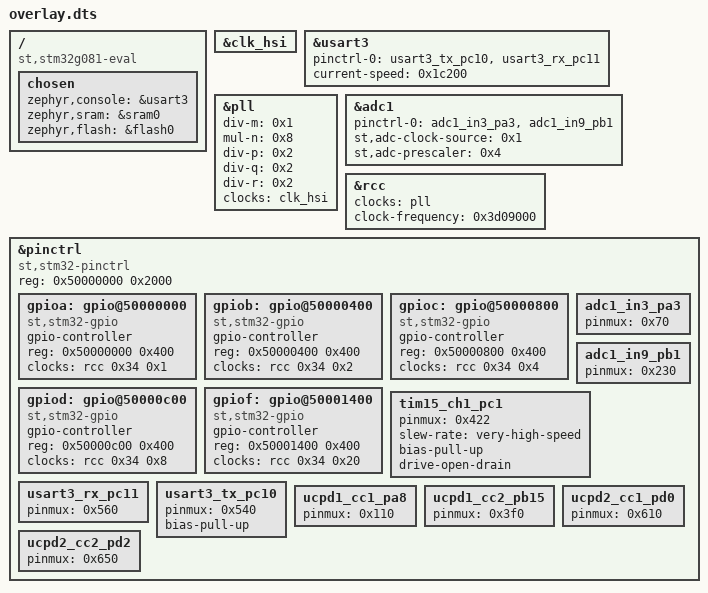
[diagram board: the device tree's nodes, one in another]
/ {
	compatible = "st,stm32g081-eval";
	chosen {
		zephyr,console = &usart3;
		zephyr,sram = &sram0;
		zephyr,flash = &flash0;
	};
};
&clk_hsi{
	status = "okay";
};
&usart3{
	status = "okay";
	pinctrl-0 = < &usart3_tx_pc10 &usart3_rx_pc11 >;
	pinctrl-names = "default";
	current-speed = < 0x1c200 >;
};
&pll{
	status = "okay";
	div-m = < 0x1 >;
	mul-n = < 0x8 >;
	div-p = < 0x2 >;
	div-q = < 0x2 >;
	div-r = < 0x2 >;
	clocks = < &clk_hsi >;
};
&adc1{
	status = "okay";
	pinctrl-0 = < &adc1_in3_pa3 &adc1_in9_pb1 >;
	pinctrl-names = "default";
	st,adc-clock-source = < 0x1 >;
	st,adc-prescaler = < 0x4 >;
	#address-cells = < 0x1 >;
	#size-cells = < 0x0 >;
};
&rcc{
	clocks = < &pll >;
	clock-frequency = < 0x3d09000 >;
};
&pinctrl{
	compatible = "st,stm32-pinctrl";
	#address-cells = < 0x1 >;
	#size-cells = < 0x1 >;
	reg = < 0x50000000 0x2000 >;
	gpioa: gpio@50000000 {
		compatible = "st,stm32-gpio";
		gpio-controller;
		#gpio-cells = < 0x2 >;
		reg = < 0x50000000 0x400 >;
		clocks = < &rcc 0x34 0x1 >;
	};
	gpiob: gpio@50000400 {
		compatible = "st,stm32-gpio";
		gpio-controller;
		#gpio-cells = < 0x2 >;
		reg = < 0x50000400 0x400 >;
		clocks = < &rcc 0x34 0x2 >;
	};
	gpioc: gpio@50000800 {
		compatible = "st,stm32-gpio";
		gpio-controller;
		#gpio-cells = < 0x2 >;
		reg = < 0x50000800 0x400 >;
		clocks = < &rcc 0x34 0x4 >;
	};
	gpiod: gpio@50000c00 {
		compatible = "st,stm32-gpio";
		gpio-controller;
		#gpio-cells = < 0x2 >;
		reg = < 0x50000c00 0x400 >;
		clocks = < &rcc 0x34 0x8 >;
	};
	gpiof: gpio@50001400 {
		compatible = "st,stm32-gpio";
		gpio-controller;
		#gpio-cells = < 0x2 >;
		reg = < 0x50001400 0x400 >;
		clocks = < &rcc 0x34 0x20 >;
	};
	adc1_in3_pa3: adc1_in3_pa3 {
		pinmux = < 0x70 >;
	};
	adc1_in9_pb1: adc1_in9_pb1 {
		pinmux = < 0x230 >;
	};
	tim15_ch1_pc1: tim15_ch1_pc1 {
		pinmux = < 0x422 >;
		slew-rate = "very-high-speed";
		bias-pull-up;
		drive-open-drain;
	};
	usart3_rx_pc11: usart3_rx_pc11 {
		pinmux = < 0x560 >;
	};
	usart3_tx_pc10: usart3_tx_pc10 {
		pinmux = < 0x540 >;
		bias-pull-up;
	};
	ucpd1_cc1_pa8: ucpd1_cc1_pa8 {
		pinmux = < 0x110 >;
	};
	ucpd1_cc2_pb15: ucpd1_cc2_pb15 {
		pinmux = < 0x3f0 >;
	};
	ucpd2_cc1_pd0: ucpd2_cc1_pd0 {
		pinmux = < 0x610 >;
	};
	ucpd2_cc2_pd2: ucpd2_cc2_pd2 {
		pinmux = < 0x650 >;
	};
};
